# EZR32LG230F256R60 register map
File version: 5.8.2
CPU: CM3 r2p1, little endian, MPU, no FPU, 3 interrupt priority bits
Registers are 32-bit, read-write, reset 0x0 unless marked. A register's access mark holds for its fields unless they carry their own. Offsets are from the block's base; [hi:lo] are bit positions; {n}, {i} and the like mark numbered series.

## LEUART0
Base 0x40084000
Same registers: LEUART1 0x40084400
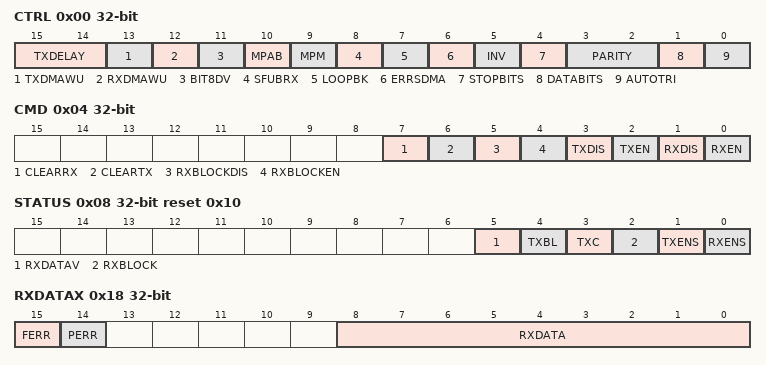
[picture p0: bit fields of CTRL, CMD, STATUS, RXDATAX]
0x00 CTRL — Control Register
  [15:14] TXDELAY — TX Delay Transmission
    0=NONE (Frames are transmitted immediately); 1=SINGLE (Transmission of new frames are delayed by a single baud period); 2=DOUBLE (Transmission of new frames are delayed by two baud periods); 3=TRIPLE (Transmission of new frames are delayed by three baud periods)
  [13] TXDMAWU — TX DMA Wakeup
  [12] RXDMAWU — RX DMA Wakeup
  [11] BIT8DV — Bit 8 Default Value
  [10] MPAB — Multi-Processor Address-Bit
  [9] MPM — Multi-Processor Mode
  [8] SFUBRX — Start-Frame UnBlock RX
  [7] LOOPBK — Loopback Enable
  [6] ERRSDMA — Clear RX DMA On Error
  [5] INV — Invert Input And Output
  [4] STOPBITS — Stop-Bit Mode
  [3:2] PARITY — Parity-Bit Mode
    0=NONE (Parity bits are not used); 2=EVEN (Even parity are used. Parity bits are automatically generated and checked by hardware.); 3=ODD (Odd parity is used. Parity bits are automatically generated and checked by hardware.)
  [1] DATABITS — Data-Bit Mode
  [0] AUTOTRI — Automatic Transmitter Tristate
0x04 CMD wo — Command Register
  [7] CLEARRX
  [6] CLEARTX
  [5] RXBLOCKDIS — Receiver Block Disable
  [4] RXBLOCKEN — Receiver Block Enable
  [3] TXDIS — Transmitter Disable
  [2] TXEN — Transmitter Enable
  [1] RXDIS — Receiver Disable
  [0] RXEN — Receiver Enable
0x08 STATUS ro reset 0x10
  [5] RXDATAV — RX Data Valid
  [4] TXBL — TX Buffer Level
  [3] TXC — TX Complete
  [2] RXBLOCK — Block Incoming Data
  [1] TXENS — Transmitter Enable Status
  [0] RXENS — Receiver Enable Status
0x0C CLKDIV — Clock Control Register
  [14:3] DIV — Fractional Clock Divider
0x10 STARTFRAME
  [8:0] STARTFRAME
0x14 SIGFRAME — Signal Frame Register
  [8:0] SIGFRAME — Signal Frame
0x18 RXDATAX ro read-has-side-effects — Receive Buffer Data Extended Register
  [15] FERR — Receive Data Framing Error
  [14] PERR — Receive Data Parity Error
  [8:0] RXDATA
0x1C RXDATA ro read-has-side-effects — Receive Buffer Data Register
  [7:0] RXDATA
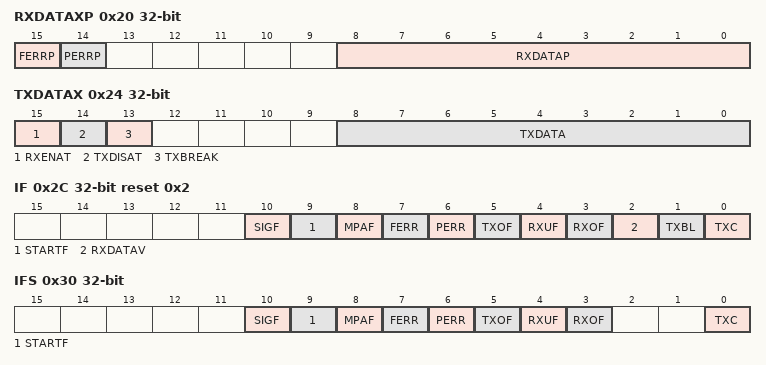
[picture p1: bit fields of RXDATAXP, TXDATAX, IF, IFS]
0x20 RXDATAXP ro — Receive Buffer Data Extended Peek Register
  [15] FERRP — Receive Data Framing Error Peek
  [14] PERRP — Receive Data Parity Error Peek
  [8:0] RXDATAP — RX Data Peek
0x24 TXDATAX wo — Transmit Buffer Data Extended Register
  [15] RXENAT — Enable RX After Transmission
  [14] TXDISAT — Disable TX After Transmission
  [13] TXBREAK — Transmit Data As Break
  [8:0] TXDATA
0x28 TXDATA wo — Transmit Buffer Data Register
  [7:0] TXDATA
0x2C IF ro reset 0x2 — Interrupt Flag Register
  [10] SIGF — Signal Frame Interrupt Flag
  [9] STARTF — Start Frame Interrupt Flag
  [8] MPAF — Multi-Processor Address Frame Interrupt Flag
  [7] FERR — Framing Error Interrupt Flag
  [6] PERR — Parity Error Interrupt Flag
  [5] TXOF — TX Overflow Interrupt Flag
  [4] RXUF — RX Underflow Interrupt Flag
  [3] RXOF — RX Overflow Interrupt Flag
  [2] RXDATAV — RX Data Valid Interrupt Flag
  [1] TXBL — TX Buffer Level Interrupt Flag
  [0] TXC — TX Complete Interrupt Flag
0x30 IFS wo — Interrupt Flag Set Register
  [10] SIGF — Set Signal Frame Interrupt Flag
  [9] STARTF — Set Start Frame Interrupt Flag
  [8] MPAF — Set Multi-Processor Address Frame Interrupt Flag
  [7] FERR — Set Framing Error Interrupt Flag
  [6] PERR — Set Parity Error Interrupt Flag
  [5] TXOF — Set TX Overflow Interrupt Flag
  [4] RXUF — Set RX Underflow Interrupt Flag
  [3] RXOF — Set RX Overflow Interrupt Flag
  [0] TXC — Set TX Complete Interrupt Flag
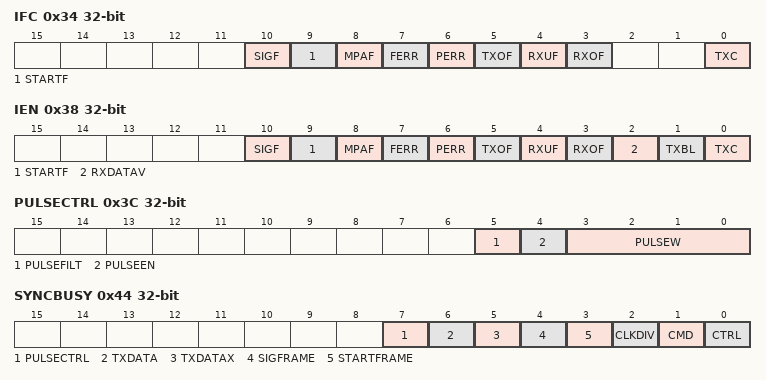
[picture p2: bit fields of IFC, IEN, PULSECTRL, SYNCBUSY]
0x34 IFC wo — Interrupt Flag Clear Register
  [10] SIGF — Clear Signal-Frame Interrupt Flag
  [9] STARTF — Clear Start-Frame Interrupt Flag
  [8] MPAF — Clear Multi-Processor Address Frame Interrupt Flag
  [7] FERR — Clear Framing Error Interrupt Flag
  [6] PERR — Clear Parity Error Interrupt Flag
  [5] TXOF — Clear TX Overflow Interrupt Flag
  [4] RXUF — Clear RX Underflow Interrupt Flag
  [3] RXOF — Clear RX Overflow Interrupt Flag
  [0] TXC — Clear TX Complete Interrupt Flag
0x38 IEN — Interrupt Enable Register
  [10] SIGF — Signal Frame Interrupt Enable
  [9] STARTF — Start Frame Interrupt Enable
  [8] MPAF — Multi-Processor Address Frame Interrupt Enable
  [7] FERR — Framing Error Interrupt Enable
  [6] PERR — Parity Error Interrupt Enable
  [5] TXOF — TX Overflow Interrupt Enable
  [4] RXUF — RX Underflow Interrupt Enable
  [3] RXOF — RX Overflow Interrupt Enable
  [2] RXDATAV — RX Data Valid Interrupt Enable
  [1] TXBL — TX Buffer Level Interrupt Enable
  [0] TXC — TX Complete Interrupt Enable
0x3C PULSECTRL — Pulse Control Register
  [5] PULSEFILT — Pulse Filter
  [4] PULSEEN — Pulse Generator/Extender Enable
  [3:0] PULSEW — Pulse Width
0x40 FREEZE
  [0] REGFREEZE — Register Update Freeze
0x44 SYNCBUSY ro — Synchronization Busy Register
  [7] PULSECTRL — PULSECTRL Register Busy
  [6] TXDATA — TXDATA Register Busy
  [5] TXDATAX — TXDATAX Register Busy
  [4] SIGFRAME — SIGFRAME Register Busy
  [3] STARTFRAME — STARTFRAME Register Busy
  [2] CLKDIV — CLKDIV Register Busy
  [1] CMD — CMD Register Busy
  [0] CTRL — CTRL Register Busy
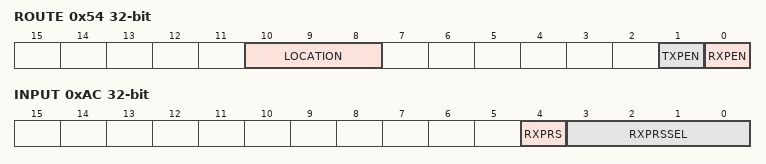
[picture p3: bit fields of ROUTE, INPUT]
0x54 ROUTE — I/O Routing Register
  [10:8] LOCATION — I/O Location
    {v}=LOC{v} (Location {v}) (v=0..4)
  [1] TXPEN — TX Pin Enable
  [0] RXPEN — RX Pin Enable
0xAC INPUT — LEUART Input Register
  [4] RXPRS — PRS RX Enable
  [3:0] RXPRSSEL — RX PRS Channel Select
    {v}=PRSCH{v} (PRS Channel {v} selected) (v=0..11)

## Notices in the file
# License
Copyright 2019 Silicon Laboratories Inc. www.silabs.com
SPDX-License-Identifier: Zlib
The licensor of this software is Silicon Laboratories Inc.
This software is provided 'as-is', without any express or implied
warranty. In no event will the authors be held liable for any damages
arising from the use of this software.
Permission is granted to anyone to use this software for any purpose,
including commercial applications, and to alter it and redistribute it
freely, subject to the following restrictions:
1. The origin of this software must not be misrepresented; you must not
claim that you wrote the original software. If you use this software
in a product, an acknowledgment in the product documentation would be
appreciated but is not required.
2. Altered source versions must be plainly marked as such, and must not be
misrepresented as being the original software.
3. This notice may not be removed or altered from any source distribution.
